AUTOSAR XML (schema 4-2-2)
package /AUTOSAR_Dcm/SwComponentTypes
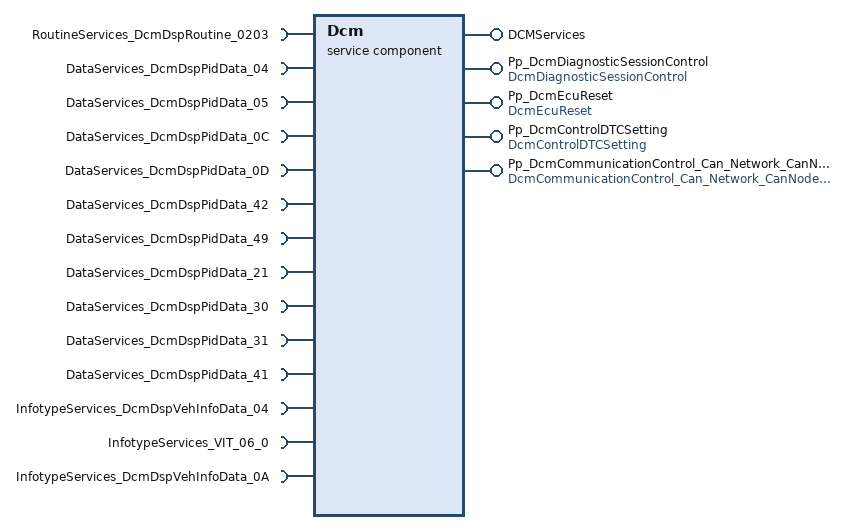
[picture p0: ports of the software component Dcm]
  service sw component type Dcm
    5 x provide port:
      DCMServices: provided-interface=DCMServices
        provided-com-specs:
          operation=GetActiveProtocol, queue-length=1
          operation=SetActiveDiagnostic, queue-length=1
          operation=GetSesCtrlType, queue-length=1
          operation=GetSecurityLevel, queue-length=1
          operation=ResetToDefaultSession, queue-length=1
      Pp_DcmDiagnosticSessionControl: mode-switch-sender-com-spec{mode-group=MDGP_DcmDiagnosticSessionControl, queue-length=1}, provided-interface=DcmDiagnosticSessionControl
      Pp_DcmEcuReset: mode-switch-sender-com-spec{mode-group=MDGP_DcmEcuReset, queue-length=1}, provided-interface=DcmEcuReset
      Pp_DcmControlDTCSetting: mode-switch-sender-com-spec{mode-group=MDGP_DcmControlDTCSetting, queue-length=1}, provided-interface=DcmControlDTCSetting
      Pp_DcmCommunicationControl_Can_Network_CanNodeNum_01: mode-switch-sender-com-spec{mode-group=MDGP_DcmCommunicationControl_Can_Network_CanNodeNum_01, queue-length=1}, provided-interface=DcmCommunicationControl_Can_Network_CanNodeNum_01
    14 x require port:
      RoutineServices_DcmDspRoutine_0203: required-interface=RoutineServices_DcmDspRoutine_0203
      DataServices_DcmDspPidData_04: required-interface=DataServices_DcmDspPidData_04
      DataServices_DcmDspPidData_05: required-interface=DataServices_DcmDspPidData_05
      DataServices_DcmDspPidData_0C: required-interface=DataServices_DcmDspPidData_0C
      DataServices_DcmDspPidData_0D: required-interface=DataServices_DcmDspPidData_0D
      DataServices_DcmDspPidData_42: required-interface=DataServices_DcmDspPidData_42
      DataServices_DcmDspPidData_49: required-interface=DataServices_DcmDspPidData_49
      DataServices_DcmDspPidData_21: required-interface=DataServices_DcmDspPidData_21
      DataServices_DcmDspPidData_30: required-interface=DataServices_DcmDspPidData_30
      DataServices_DcmDspPidData_31: required-interface=DataServices_DcmDspPidData_31
      DataServices_DcmDspPidData_41: required-interface=DataServices_DcmDspPidData_41
      InfotypeServices_DcmDspVehInfoData_04: required-interface=InfotypeServices_DcmDspVehInfoData_04
      InfotypeServices_VIT_06_0: required-interface=InfotypeServices_VIT_06_0
      InfotypeServices_DcmDspVehInfoData_0A: required-interface=InfotypeServices_DcmDspVehInfoData_0A
    behavior IntBeh_Dcm: data-type-mapping=[DTS_DcmDiagnosticSessionControl, DTS_DcmEcuReset, DTS_DcmControlDTCSetting, DTS_DcmCommunicationControl_Can_Network_CanNodeNum_01], included-data-type-set=data-type=[Dcm_SecLevelType, Dcm_SesCtrlType, Dcm_ProtocolType, Dcm_NegativeResponseCodeType, Dcm_ConfirmationStatusType, Dcm_OpStatusType, Dcm_DidSupportedType]
      5 x operation invoked event:
        OpInvEvent_DCMServices_GAP: start-on-event=Dcm_GetActiveProtocol, operation=DCMServices.GetActiveProtocol
        OpInvEvent_DCMServices_SAD: start-on-event=Dcm_SetActiveDiagnostic, operation=DCMServices.SetActiveDiagnostic
        OpInvEvent_DCMServices_GSCT: start-on-event=Dcm_GetSesCtrlType, operation=DCMServices.GetSesCtrlType
        OpInvEvent_DCMServices_GSL: start-on-event=Dcm_GetSecurityLevel, operation=DCMServices.GetSecurityLevel
        OpInvEvent_DCMServices_RD: start-on-event=Dcm_ResetToDefaultSession, operation=DCMServices.ResetToDefaultSession
      port-api-options:
        enable-take-address=true, indirect-api=false, port=RoutineServices_DcmDspRoutine_0203
        enable-take-address=true, indirect-api=false, port=InfotypeServices_DcmDspVehInfoData_04
        enable-take-address=true, indirect-api=false, port=InfotypeServices_VIT_06_0
        enable-take-address=true, indirect-api=false, port=InfotypeServices_DcmDspVehInfoData_0A
        enable-take-address=true, indirect-api=false, port=DataServices_DcmDspPidData_04
        enable-take-address=true, indirect-api=false, port=DataServices_DcmDspPidData_05
        enable-take-address=true, indirect-api=false, port=DataServices_DcmDspPidData_0C
        enable-take-address=true, indirect-api=false, port=DataServices_DcmDspPidData_0D
        enable-take-address=true, indirect-api=false, port=DataServices_DcmDspPidData_42
        enable-take-address=true, indirect-api=false, port=DataServices_DcmDspPidData_49
        enable-take-address=true, indirect-api=false, port=DataServices_DcmDspPidData_21
        enable-take-address=true, indirect-api=false, port=DataServices_DcmDspPidData_30
        enable-take-address=true, indirect-api=false, port=DataServices_DcmDspPidData_31
        enable-take-address=true, indirect-api=false, port=DataServices_DcmDspPidData_41
      6 x runnable:
        Dcm_MainFunction
          4 x mode switch point:
            ModeSwitchPoint_0: mode-group=Pp_DcmDiagnosticSessionControl.MDGP_DcmDiagnosticSessionControl
            ModeSwitchPoint_1: mode-group=Pp_DcmEcuReset.MDGP_DcmEcuReset
            ModeSwitchPoint_3: mode-group=Pp_DcmControlDTCSetting.MDGP_DcmControlDTCSetting
            ModeSwitchPoint_Can_Network_CanNodeNum_01: mode-group=Pp_DcmCommunicationControl_Can_Network_CanNodeNum_01.MDGP_DcmCommunicationControl_Can_Network_CanNodeNum_01
          15 x sync call, all with timeout=0.0:
            SSC_Rout_DcmDspRoutine_0203_Start: operation=RoutineServices_DcmDspRoutine_0203.Start
            SSC_Rout_DcmDspRoutine_0203_ReqRes: operation=RoutineServices_DcmDspRoutine_0203.RequestResults
            DataServices_DcmDspPidData_04_RData: operation=DataServices_DcmDspPidData_04.ReadData
            DataServices_DcmDspPidData_05_RData: operation=DataServices_DcmDspPidData_05.ReadData
            DataServices_DcmDspPidData_0C_RData: operation=DataServices_DcmDspPidData_0C.ReadData
            DataServices_DcmDspPidData_0D_RData: operation=DataServices_DcmDspPidData_0D.ReadData
            DataServices_DcmDspPidData_42_RData: operation=DataServices_DcmDspPidData_42.ReadData
            DataServices_DcmDspPidData_49_RData: operation=DataServices_DcmDspPidData_49.ReadData
            DataServices_DcmDspPidData_21_RData: operation=DataServices_DcmDspPidData_21.ReadData
            DataServices_DcmDspPidData_30_RData: operation=DataServices_DcmDspPidData_30.ReadData
            DataServices_DcmDspPidData_31_RData: operation=DataServices_DcmDspPidData_31.ReadData
            DataServices_DcmDspPidData_41_RData: operation=DataServices_DcmDspPidData_41.ReadData
            SSC_DcmDspVehInfoData_04_GInfoType: operation=InfotypeServices_DcmDspVehInfoData_04.GetInfotypeValueData
            SSC_VIT_06_0_GInfoType: operation=InfotypeServices_VIT_06_0.GetInfotypeValueData
            SSC_DcmDspVehInfoData_0A_GInfoType: operation=InfotypeServices_DcmDspVehInfoData_0A.GetInfotypeValueData
        Dcm_GetActiveProtocol: can-be-invoked-concurrently=true
        Dcm_SetActiveDiagnostic: can-be-invoked-concurrently=true
        Dcm_GetSesCtrlType: can-be-invoked-concurrently=true
        Dcm_GetSecurityLevel: can-be-invoked-concurrently=true
        Dcm_ResetToDefaultSession: can-be-invoked-concurrently=true
package /AUTOSAR_Dcm/SwcImplementations
  swc implementation Impl_Dcm: programming-language=C, sw-version=42.9.0.0, swc-bsw-mapping=SwcBswMappings, vendor-id=6, behavior=IntBeh_Dcm
    code-descriptors:
      code CodeDescr_Dcm: artifact-descriptors=autosar-engineering-object={short-label=Code_0, category=SWSRC}
package /AUTOSAR_Dcm/CompuMethods
  compu method Dcm_RidSupportedType_Values: 0=DCM_RID_SUPPORTED_IN_RANGE, 1=DCM_RID_NOT_SUPPORTED
  compu method inputOutputControlParameterType_Values: 255=DCM_IDLE, 3=DCM_SHORT_TERM_ADJUSTMENT, 2=DCM_FREEZE_CURRENT_STATE, 1=DCM_RESET_TO_DEFAULT, 0=DCM_RETURN_CONTROL_TO_ECU
  compu method IOOperationResponse_Values: 255=DCM_IDLE, 0=DCM_POSITIVE_RESPONSE, 16=DCM_GENERAL_REJECT, 33=DCM_BUSY_REPEAT_REQUEST, 34=DCM_CONDITIONS_NOT_CORRECT, 38=DCM_FAILURE_PREVENTS_EXECUTION, 49=DCM_REQUEST_OUT_OF_RANGE, 120=DCM_RESPONSE_PENDING
package /AUTOSAR_Dcm/ImplementationDataTypes
  24 x impl type:
    Dcm_SesCtrlType: compu {1=DCM_DEFAULT_SESSION, 2=DCM_PROGRAMMING_SESSION, 3=DCM_EXTENDED_DIAGNOSTIC_SESSION, 4=DCM_SAFETY_SYSTEM_DIAGNOSTIC_SESSION}, implementation-data-type=uint8
    Dcm_NegativeResponseCodeType: compu {0=DCM_POS_RESP, 17=DCM_E_SERVICENOTSUPPORTED, 18=DCM_E_SUBFUNCTIONNOTSUPPORTED, 19=DCM_E_INCORRECTMESSAGELENGTHORINVALIDFORMAT, 20=DCM_E_RESPONSETOOLONG, 53=DCM_E_INVALIDKEY, 54=DCM_E_EXCEEDNUMBEROFATTEMPTS, 55=DCM_E_REQUIREDTIMEDELAYNOTEXPIRED, 112=DCM_E_UPLOADDOWNLOADNOTACCEPTED, 113=DCM_E_TRANSFERDATASUSPENDED, 115=DCM_E_WRONGBLOCKSEQUENCECOUNTER, 127=DCM_E_SERVICENOTSUPPORTEDINACTIVESESSION, 140=DCM_E_TRANSMISSIONRANGENOTINNEUTRAL, 34=DCM_E_CONDITIONSNOTCORRECT, 16=DCM_E_GENERALREJECT, 33=DCM_E_BUSYREPEATREQUEST, 36=DCM_E_REQUESTSEQUENCEERROR, 37=DCM_E_NORESPONSEFROMSUBNETCOMPONENT, 38=DCM_E_FAILUREPREVENTSEXECUTIONOFREQUESTEDACTION, 49=DCM_E_REQUESTOUTOFRANGE, 51=DCM_E_SECURITYACCESSDENIED, 114=DCM_E_GENERALPROGRAMMINGFAILURE, 126=DCM_E_SUBFUNCTIONNOTSUPPORTEDINACTIVESESSION, 129=DCM_E_RPMTOOHIGH, 130=DCM_E_RPMTOOLOW, 131=DCM_E_ENGINEISRUNNING, 132=DCM_E_ENGINEISNOTRUNNING, 133=DCM_E_ENGINERUNTIMETOOLOW, 134=DCM_E_TEMPERATURETOOHIGH, 135=DCM_E_TEMPERATURETOOLOW, 136=DCM_E_VEHICLESPEEDTOOHIGH, 137=DCM_E_VEHICLESPEEDTOOLOW, 138=DCM_E_THROTTLE_PEDALTOOHIGH, 139=DCM_E_THROTTLE_PEDALTOOLOW, 141=DCM_E_TRANSMISSIONRANGENOTINGEAR, 146=DCM_E_VOLTAGETOOHIGH, 143=DCM_E_BRAKESWITCH_NOTCLOSED, 144=DCM_E_SHIFTERLEVERNOTINPARK, 145=DCM_E_TORQUECONVERTERCLUTCHLOCKED, 147=DCM_E_VOLTAGETOOLOW, 0=DCM_E_POSITIVERESPONSE, 120=DCM_E_REQUESTCORRECTLYRECEIVEDRESPONSEPENDING, 148=DCM_E_RESOURCETEMPORARILYNOTAVAILABLE, 240..249=DCM_E_VMSCNC_0..DCM_E_VMSCNC_9, 250=DCM_E_VMSCNC_A, 251=DCM_E_VMSCNC_B, 252=DCM_E_VMSCNC_C, 253=DCM_E_VMSCNC_D, 254=DCM_E_VMSCNC_E}, implementation-data-type=uint8
    Dcm_ConfirmationStatusType: compu {0=DCM_RES_POS_OK, 1=DCM_RES_POS_NOT_OK, 2=DCM_RES_NEG_OK, 3=DCM_RES_NEG_NOT_OK}, implementation-data-type=uint8
    Dcm_ProtocolType: compu {0=DCM_OBD_ON_CAN, 1=DCM_OBD_ON_FLEXRAY, 2=DCM_OBD_ON_IP, 3=DCM_UDS_ON_CAN, 4=DCM_UDS_ON_FLEXRAY, 5=DCM_UDS_ON_IP, 6=DCM_ROE_ON_CAN, 7=DCM_ROE_ON_FLEXRAY, 8=DCM_ROE_ON_IP, 9=DCM_PERIODICTRANS_ON_CAN, 10=DCM_PERIODICTRANS_ON_FLEXRAY, 11=DCM_PERIODICTRANS_ON_IP, 12=DCM_NO_ACTIVE_PROTOCOL, 144=DCM_ACEA_ON_CAN, 145=DCM_ACEA_ON_FLEXRAY, 128=DCM_KWP_ON_KLINE, 129=DCM_KWP_ON_CAN, 160=DCM_CARB_ON_KLINE, 161=DCM_OBD_ON_KLINE, 240..254=DCM_SUPPLIER_1..DCM_SUPPLIER_15}, implementation-data-type=uint8
    Dcm_SecLevelType: compu {1=DCM_SEC_LEV_L1}, implementation-data-type=uint8
    Dcm_StartDataOut_DcmDspRoutine_0203_DcmDspStartRoutineOutSignalType: implementation-data-type=Dcm_StartDataOut_DcmDspRoutine_0203_DcmDspStartRoutineOutSignalPrimitivType
    Dcm_StartDataOut_DcmDspRoutine_0203_DcmDspStartRoutineOutSignalPrimitivType: implementation-data-type=uint8
    Dcm_RequestDataOut_DcmDspRoutine_0203_DcmDspRequestRoutineResultsOutSignal_0Type: implementation-data-type=Dcm_RequestDataOut_DcmDspRoutine_0203_DcmDspRequestRoutineResultsOutSignal_0PrimitivType
    Dcm_RequestDataOut_DcmDspRoutine_0203_DcmDspRequestRoutineResultsOutSignal_0PrimitivType: implementation-data-type=uint8
    Dcm_DataArrayTypeUint8_DcmDspPidData_04Type: category=ARRAY
      element ReadDataArray: array-size=1, array-size-semantics=FIXED-SIZE, implementation-data-type=uint8
    Dcm_DataArrayTypeUint8_DcmDspPidData_05Type: category=ARRAY
      element ReadDataArray: array-size=1, array-size-semantics=FIXED-SIZE, implementation-data-type=uint8
    Dcm_DataArrayTypeUint8_DcmDspPidData_0CType: category=ARRAY
      element ReadDataArray: array-size=2, array-size-semantics=FIXED-SIZE, implementation-data-type=uint8
    Dcm_DataArrayTypeUint8_DcmDspPidData_0DType: category=ARRAY
      element ReadDataArray: array-size=1, array-size-semantics=FIXED-SIZE, implementation-data-type=uint8
    Dcm_DataArrayTypeUint8_DcmDspPidData_42Type: category=ARRAY
      element ReadDataArray: array-size=2, array-size-semantics=FIXED-SIZE, implementation-data-type=uint8
    Dcm_DataArrayTypeUint8_DcmDspPidData_49Type: category=ARRAY
      element ReadDataArray: array-size=1, array-size-semantics=FIXED-SIZE, implementation-data-type=uint8
    Dcm_DataArrayTypeUint8_DcmDspPidData_21Type: category=ARRAY
      element ReadDataArray: array-size=2, array-size-semantics=FIXED-SIZE, implementation-data-type=uint8
    Dcm_DataArrayTypeUint8_DcmDspPidData_30Type: category=ARRAY
      element ReadDataArray: array-size=1, array-size-semantics=FIXED-SIZE, implementation-data-type=uint8
    Dcm_DataArrayTypeUint8_DcmDspPidData_31Type: category=ARRAY
      element ReadDataArray: array-size=2, array-size-semantics=FIXED-SIZE, implementation-data-type=uint8
    Dcm_DataArrayTypeUint8_DcmDspPidData_41Type: category=ARRAY
      element ReadDataArray: array-size=4, array-size-semantics=FIXED-SIZE, implementation-data-type=uint8
    Dcm_OpStatusType: compu {0=DCM_INITIAL, 1=DCM_PENDING, 2=DCM_CANCEL, 3=DCM_FORCE_RCRRP_OK}, implementation-data-type=uint8
    Dcm_DidSupportedType: compu {0=DCM_DID_SUPPORTED, 1=DCM_DID_NOT_SUPPORTED}, implementation-data-type=uint8
    Dcm_InfoTypeServicesArray_DcmDspVehInfoData_04Type: category=ARRAY
      element Dcm_InfoTypeServicesArray_DcmDspVehInfoData_04Type: array-size=16, array-size-semantics=FIXED-SIZE, implementation-data-type=uint8
    Dcm_InfoTypeServicesArray_VIT_06_0Type: category=ARRAY
      element Dcm_InfoTypeServicesArray_VIT_06_0Type: array-size=4, array-size-semantics=FIXED-SIZE, implementation-data-type=uint8
    Dcm_InfoTypeServicesArray_DcmDspVehInfoData_0AType: category=ARRAY
      element Dcm_InfoTypeServicesArray_DcmDspVehInfoData_0AType: array-size=20, array-size-semantics=FIXED-SIZE, implementation-data-type=uint8
package /AUTOSAR_Dcm/DataTypeMappingSets
  4 x data type mapping set:
    DTS_DcmDiagnosticSessionControl: mode-request-type-map{implementation-data-type=uint8, mode-group=DcmDiagnosticSessionControl}
    DTS_DcmEcuReset: mode-request-type-map{implementation-data-type=uint8, mode-group=DcmEcuReset}
    DTS_DcmControlDTCSetting: mode-request-type-map{implementation-data-type=uint8, mode-group=DcmControlDTCSetting}
    DTS_DcmCommunicationControl_Can_Network_CanNodeNum_01: mode-request-type-map{implementation-data-type=uint8, mode-group=DcmCommunicationControl_Can_Network_CanNodeNum_01}
package /AUTOSAR_Dcm/SwcBswMappings
  swc bsw mapping SwcBswMappings: bsw-behavior=BswInternalBehavior, swc-bsw-runnable-mapping{bsw-entity=BSWSE_DcmMainFunction, swc-runnable=Dcm_MainFunction}, swc-behavior=IntBeh_Dcm
    synchronized-mode-groups:
      bsw-mode-group=DcmDiagnosticSessionControl, swc-mode-group=Pp_DcmDiagnosticSessionControl.MDGP_DcmDiagnosticSessionControl
      bsw-mode-group=DcmEcuReset, swc-mode-group=Pp_DcmEcuReset.MDGP_DcmEcuReset
      bsw-mode-group=DcmControlDTCSetting, swc-mode-group=Pp_DcmControlDTCSetting.MDGP_DcmControlDTCSetting
      bsw-mode-group=DcmCommunicationControl_Can_Network_CanNodeNum_01, swc-mode-group=Pp_DcmCommunicationControl_Can_Network_CanNodeNum_01.MDGP_DcmCommunicationControl_Can_Network_CanNodeNum_01
package /AUTOSAR_Dcm/PortInterfaces
  15 x client server interface, all with is-service=true:
    DataServices_DcmDspPidData_04
      operation ReadData: possible-error=[DataServices_DcmDspPidData_04/E_OK, DataServices_DcmDspPidData_04/E_NOT_OK]
        arg Data: type=Dcm_DataArrayTypeUint8_DcmDspPidData_04Type, direction=OUT
      error E_OK: error-code=0
      error E_NOT_OK: error-code=1
    DataServices_DcmDspPidData_05
      operation ReadData: possible-error=[DataServices_DcmDspPidData_05/E_OK, DataServices_DcmDspPidData_05/E_NOT_OK]
        arg Data: type=Dcm_DataArrayTypeUint8_DcmDspPidData_05Type, direction=OUT
      error E_OK: error-code=0
      error E_NOT_OK: error-code=1
    DataServices_DcmDspPidData_0C
      operation ReadData: possible-error=[DataServices_DcmDspPidData_0C/E_OK, DataServices_DcmDspPidData_0C/E_NOT_OK]
        arg Data: type=Dcm_DataArrayTypeUint8_DcmDspPidData_0CType, direction=OUT
      error E_OK: error-code=0
      error E_NOT_OK: error-code=1
    DataServices_DcmDspPidData_0D
      operation ReadData: possible-error=[DataServices_DcmDspPidData_0D/E_OK, DataServices_DcmDspPidData_0D/E_NOT_OK]
        arg Data: type=Dcm_DataArrayTypeUint8_DcmDspPidData_0DType, direction=OUT
      error E_OK: error-code=0
      error E_NOT_OK: error-code=1
    DataServices_DcmDspPidData_42
      operation ReadData: possible-error=[DataServices_DcmDspPidData_42/E_OK, DataServices_DcmDspPidData_42/E_NOT_OK]
        arg Data: type=Dcm_DataArrayTypeUint8_DcmDspPidData_42Type, direction=OUT
      error E_OK: error-code=0
      error E_NOT_OK: error-code=1
    DataServices_DcmDspPidData_49
      operation ReadData: possible-error=[DataServices_DcmDspPidData_49/E_OK, DataServices_DcmDspPidData_49/E_NOT_OK]
        arg Data: type=Dcm_DataArrayTypeUint8_DcmDspPidData_49Type, direction=OUT
      error E_OK: error-code=0
      error E_NOT_OK: error-code=1
    DataServices_DcmDspPidData_21
      operation ReadData: possible-error=[DataServices_DcmDspPidData_21/E_OK, DataServices_DcmDspPidData_21/E_NOT_OK]
        arg Data: type=Dcm_DataArrayTypeUint8_DcmDspPidData_21Type, direction=OUT
      error E_OK: error-code=0
      error E_NOT_OK: error-code=1
    DataServices_DcmDspPidData_30
      operation ReadData: possible-error=[DataServices_DcmDspPidData_30/E_OK, DataServices_DcmDspPidData_30/E_NOT_OK]
        arg Data: type=Dcm_DataArrayTypeUint8_DcmDspPidData_30Type, direction=OUT
      error E_OK: error-code=0
      error E_NOT_OK: error-code=1
    DataServices_DcmDspPidData_31
      operation ReadData: possible-error=[DataServices_DcmDspPidData_31/E_OK, DataServices_DcmDspPidData_31/E_NOT_OK]
        arg Data: type=Dcm_DataArrayTypeUint8_DcmDspPidData_31Type, direction=OUT
      error E_OK: error-code=0
      error E_NOT_OK: error-code=1
    DataServices_DcmDspPidData_41
      operation ReadData: possible-error=[DataServices_DcmDspPidData_41/E_OK, DataServices_DcmDspPidData_41/E_NOT_OK]
        arg Data: type=Dcm_DataArrayTypeUint8_DcmDspPidData_41Type, direction=OUT
      error E_OK: error-code=0
      error E_NOT_OK: error-code=1
    DCMServices
      5 x operation:
        GetActiveProtocol: possible-error=[DCMServices/E_OK, DCMServices/E_NOT_OK]
          arg ActiveProtocol: type=Dcm_ProtocolType, direction=OUT
        SetActiveDiagnostic: possible-error=DCMServices/E_OK
          arg active: type=boolean, direction=IN
        GetSesCtrlType: possible-error=[DCMServices/E_OK, DCMServices/E_NOT_OK]
          arg SesCtrlType: type=Dcm_SesCtrlType, direction=OUT
        GetSecurityLevel: possible-error=[DCMServices/E_OK, DCMServices/E_NOT_OK]
          arg SecLevel: type=Dcm_SecLevelType, direction=OUT
        ResetToDefaultSession: possible-error=[DCMServices/E_OK, DCMServices/E_NOT_OK]
      error E_OK: error-code=0
      error E_NOT_OK: error-code=1
    RoutineServices_DcmDspRoutine_0203
      operation Start: possible-error=[RoutineServices_DcmDspRoutine_0203/E_OK, RoutineServices_DcmDspRoutine_0203/E_NOT_OK, RoutineServices_DcmDspRoutine_0203/DCM_E_PENDING, DCM_E_FORCE_RCRRP]
        arg OpStatus: type=Dcm_OpStatusType, direction=IN
        arg DataOut_DcmDspStartRoutineOutSignal: type=Dcm_StartDataOut_DcmDspRoutine_0203_DcmDspStartRoutineOutSignalType, direction=OUT
        arg ErrorCode: type=Dcm_NegativeResponseCodeType, direction=OUT
      operation RequestResults: possible-error=[RoutineServices_DcmDspRoutine_0203/E_OK, RoutineServices_DcmDspRoutine_0203/E_NOT_OK, RoutineServices_DcmDspRoutine_0203/DCM_E_PENDING, DCM_E_FORCE_RCRRP]
        arg OpStatus: type=Dcm_OpStatusType, direction=IN
        arg DataOut_DcmDspRequestRoutineResultsOutSignal_0: type=Dcm_RequestDataOut_DcmDspRoutine_0203_DcmDspRequestRoutineResultsOutSignal_0Type, direction=OUT
        arg ErrorCode: type=Dcm_NegativeResponseCodeType, direction=OUT
      4 x error:
        E_OK: error-code=0
        E_NOT_OK: error-code=1
        DCM_E_PENDING: error-code=10
        DCM_E_FORCE_RCRRP: error-code=12
    InfotypeServices_DcmDspVehInfoData_04
      operation GetInfotypeValueData: possible-error=[InfotypeServices_DcmDspVehInfoData_04/E_OK, InfotypeServices_DcmDspVehInfoData_04/E_NOT_OK, InfotypeServices_DcmDspVehInfoData_04/DCM_E_PENDING]
        arg OpStatus: type=Dcm_OpStatusType, direction=IN
        arg DataValueBuffer: type=Dcm_InfoTypeServicesArray_DcmDspVehInfoData_04Type, direction=OUT
        arg DataValueBufferSize: type=uint8, direction=INOUT
      error E_OK: error-code=0
      error E_NOT_OK: error-code=1
      error DCM_E_PENDING: error-code=10
    InfotypeServices_VIT_06_0
      operation GetInfotypeValueData: possible-error=[InfotypeServices_VIT_06_0/E_OK, InfotypeServices_VIT_06_0/E_NOT_OK, InfotypeServices_VIT_06_0/DCM_E_PENDING]
        arg OpStatus: type=Dcm_OpStatusType, direction=IN
        arg DataValueBuffer: type=Dcm_InfoTypeServicesArray_VIT_06_0Type, direction=OUT
        arg DataValueBufferSize: type=uint8, direction=INOUT
      error E_OK: error-code=0
      error E_NOT_OK: error-code=1
      error DCM_E_PENDING: error-code=10
    InfotypeServices_DcmDspVehInfoData_0A
      operation GetInfotypeValueData: possible-error=[InfotypeServices_DcmDspVehInfoData_0A/E_OK, InfotypeServices_DcmDspVehInfoData_0A/E_NOT_OK, InfotypeServices_DcmDspVehInfoData_0A/DCM_E_PENDING]
        arg OpStatus: type=Dcm_OpStatusType, direction=IN
        arg DataValueBuffer: type=Dcm_InfoTypeServicesArray_DcmDspVehInfoData_0AType, direction=OUT
        arg DataValueBufferSize: type=uint8, direction=INOUT
      error E_OK: error-code=0
      error E_NOT_OK: error-code=1
      error DCM_E_PENDING: error-code=10
  4 x mode switch interface, all with is-service=true:
    DcmDiagnosticSessionControl
      mode group MDGP_DcmDiagnosticSessionControl: type=DcmDiagnosticSessionControl
    DcmEcuReset
      mode group MDGP_DcmEcuReset: type=DcmEcuReset
    DcmControlDTCSetting
      mode group MDGP_DcmControlDTCSetting: type=DcmControlDTCSetting
    DcmCommunicationControl_Can_Network_CanNodeNum_01
      mode group MDGP_DcmCommunicationControl_Can_Network_CanNodeNum_01: type=DcmCommunicationControl_Can_Network_CanNodeNum_01
